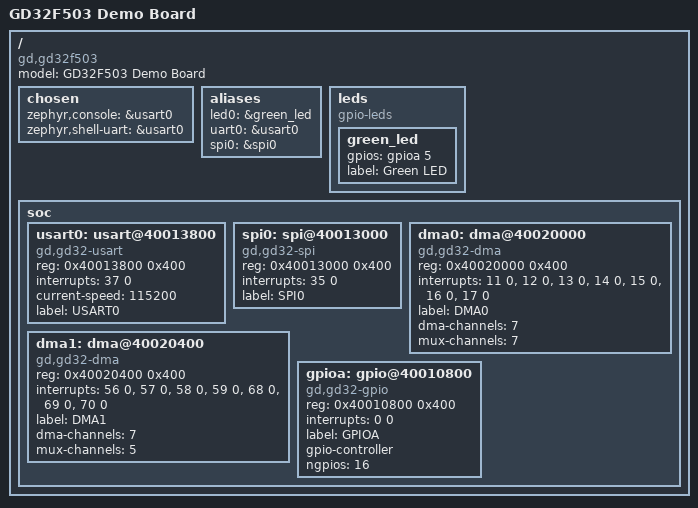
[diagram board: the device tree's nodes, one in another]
/dts-v1/;

#include <arm/gd/gd32f50x.dtsi>

/ {
    compatible = "gd,gd32f503";
    model = "GD32F503 Demo Board";

    chosen {
        zephyr,console = &usart0;
        zephyr,shell-uart = &usart0;
    };

    aliases {
        led0 = &green_led;
        uart0 = &usart0;
        spi0 = &spi0;
    };

    leds {
        compatible = "gpio-leds";
        green_led: green_led {
            gpios = <&gpioa 5 0>;
            label = "Green LED";
        };
    };

    soc {
        usart0: usart@40013800 {
            compatible = "gd,gd32-usart";
            reg = <0x40013800 0x400>;
            interrupts = <37 0>;
            status = "okay";
            current-speed = <115200>;
            label = "USART0";
        };

        spi0: spi@40013000 {
            compatible = "gd,gd32-spi";
            reg = <0x40013000 0x400>;
            interrupts = <35 0>;
            status = "okay";
            label = "SPI0";
            #address-cells = <1>;
            #size-cells = <0>;
        };

        dma0: dma@40020000 {
            compatible = "gd,gd32-dma";
            reg = <0x40020000 0x400>;
            interrupts = <11 0>, <12 0>, <13 0>, <14 0>, <15 0>, <16 0>, <17 0>;
            label = "DMA0";
            dma-channels = <7>;
            mux-channels = <7>;
            #dma-cells = <2>;
        };

        dma1: dma@40020400 {
            compatible = "gd,gd32-dma";
            reg = <0x40020400 0x400>;
            interrupts = <56 0>, <57 0>, <58 0>, <59 0>, <68 0>, <69 0>, <70 0>;
            label = "DMA1";
            dma-channels = <7>;
            mux-channels = <5>;
            #dma-cells = <2>;
        };

        gpioa: gpio@40010800 {
            compatible = "gd,gd32-gpio";
            reg = <0x40010800 0x400>;
            interrupts = <0 0>;
            label = "GPIOA";
            gpio-controller;
            #gpio-cells = <2>;
            ngpios = <16>;
        };
    };
};
